AUTOSAR XML (schema 00043)
package /vwg/applications/Basis__ICAS3_Sys_IVI_01
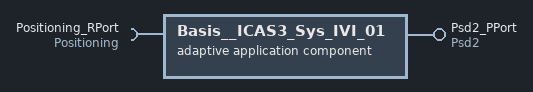
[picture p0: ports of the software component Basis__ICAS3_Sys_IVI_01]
  adaptive application sw component type Basis__ICAS3_Sys_IVI_01
    require port Positioning_RPort: required-interface=Positioning
    provide port Psd2_PPort: provided-interface=Psd2
